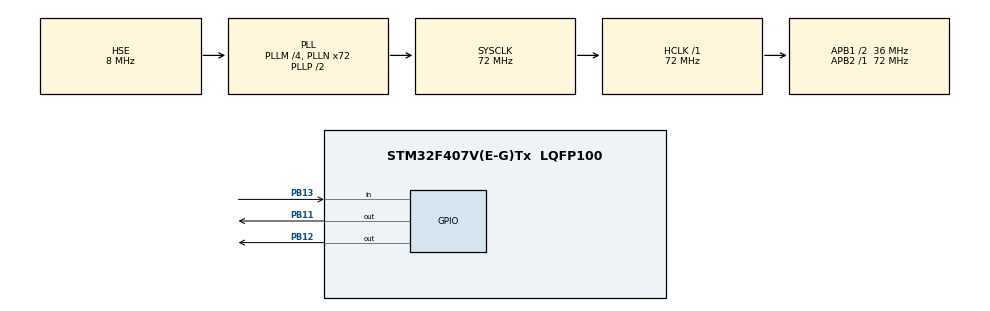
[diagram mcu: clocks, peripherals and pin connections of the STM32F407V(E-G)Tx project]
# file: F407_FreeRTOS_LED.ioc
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FREERTOS.Tasks01=defaultTask,0,128,StartDefaultTask,Default,NULL,Dynamic,NULL,NULL;myTask02,-3,128,StartTask02,Default,NULL,Dynamic,NULL,NULL
FREERTOS.configUSE_NEWLIB_REENTRANT=1
Mcu.Family=STM32F4
Mcu.Name=STM32F407V(E-G)Tx
Mcu.Package=LQFP100
NVIC.PriorityGroup=NVIC_PRIORITYGROUP_4
PB11.Signal=GPIO_Output
PB12.Signal=GPIO_Output
PB13.GPIO_PuPd=GPIO_PULLUP
PB13.Signal=GPIO_Input
PH0-OSC_IN.Mode=HSE-External-Oscillator
PH0-OSC_IN.Signal=RCC_OSC_IN
PH1-OSC_OUT.Mode=HSE-External-Oscillator
PH1-OSC_OUT.Signal=RCC_OSC_OUT
ProjectManager.HeapSize=0x200
ProjectManager.StackSize=0x400
ProjectManager.TargetToolchain=STM32CubeIDE
RCC.48MHZClocksFreq_Value=36000000
RCC.AHBFreq_Value=72000000
RCC.APB1CLKDivider=RCC_HCLK_DIV2
RCC.APB1Freq_Value=36000000
RCC.APB1TimFreq_Value=72000000
RCC.APB2Freq_Value=72000000
RCC.APB2TimFreq_Value=72000000
RCC.CortexFreq_Value=72000000
RCC.HCLKFreq_Value=72000000
RCC.HSE_VALUE=8000000
RCC.HSI_VALUE=16000000
RCC.LSE_VALUE=32768
RCC.PLLM=4
RCC.PLLN=72
RCC.PLLSourceVirtual=RCC_PLLSOURCE_HSE
RCC.SYSCLKFreq_VALUE=72000000
RCC.SYSCLKSource=RCC_SYSCLKSOURCE_PLLCLK
RCC.VCOOutputFreq_Value=144000000
VP_FREERTOS_VS_CMSIS_V1.Mode=CMSIS_V1
board=custom

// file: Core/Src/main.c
/* USER CODE BEGIN Header */
/**
  ******************************************************************************
  * @file           : main.c
  * @brief          : Main program body
  ******************************************************************************
  * @attention
  *
  * Copyright (c) 2024 STMicroelectronics.
  * All rights reserved.
  *
  * This software is licensed under terms that can be found in the LICENSE file
  * in the root directory of this software component.
  * If no LICENSE file comes with this software, it is provided AS-IS.
  *
  ******************************************************************************
  */
/* USER CODE END Header */
#include "main.h"
#include "cmsis_os.h"
#include "gpio.h"

void SystemClock_Config(void);
void MX_FREERTOS_Init(void);

int main(void)
{

  /* MCU Configuration--------------------------------------------------------*/

  /* Reset of all peripherals, Initializes the Flash interface and the Systick. */
  HAL_Init();

  /* Configure the system clock */
  SystemClock_Config();

  /* Initialize all configured peripherals */
  MX_GPIO_Init();

  /* Call init function for freertos objects (in cmsis_os2.c) */
  MX_FREERTOS_Init();

  /* Start scheduler */
  osKernelStart();

  /* We should never get here as control is now taken by the scheduler */

  /* Infinite loop */
  while (1)
  {

  }
}

void SystemClock_Config(void)
{
  RCC_OscInitTypeDef RCC_OscInitStruct = {0};
  RCC_ClkInitTypeDef RCC_ClkInitStruct = {0};

  /** Configure the main internal regulator output voltage
  */
  __HAL_RCC_PWR_CLK_ENABLE();
  __HAL_PWR_VOLTAGESCALING_CONFIG(PWR_REGULATOR_VOLTAGE_SCALE1);

  /** Initializes the RCC Oscillators according to the specified parameters
  * in the RCC_OscInitTypeDef structure.
  */
  RCC_OscInitStruct.OscillatorType = RCC_OSCILLATORTYPE_HSE;
  RCC_OscInitStruct.HSEState = RCC_HSE_ON;
  RCC_OscInitStruct.PLL.PLLState = RCC_PLL_ON;
  RCC_OscInitStruct.PLL.PLLSource = RCC_PLLSOURCE_HSE;
  RCC_OscInitStruct.PLL.PLLM = 4;
  RCC_OscInitStruct.PLL.PLLN = 72;
  RCC_OscInitStruct.PLL.PLLP = RCC_PLLP_DIV2;
  RCC_OscInitStruct.PLL.PLLQ = 4;
  if (HAL_RCC_OscConfig(&RCC_OscInitStruct) != HAL_OK)
  {
    Error_Handler();
  }

  /** Initializes the CPU, AHB and APB buses clocks
  */
  RCC_ClkInitStruct.ClockType = RCC_CLOCKTYPE_HCLK|RCC_CLOCKTYPE_SYSCLK
                              |RCC_CLOCKTYPE_PCLK1|RCC_CLOCKTYPE_PCLK2;
  RCC_ClkInitStruct.SYSCLKSource = RCC_SYSCLKSOURCE_PLLCLK;
  RCC_ClkInitStruct.AHBCLKDivider = RCC_SYSCLK_DIV1;
  RCC_ClkInitStruct.APB1CLKDivider = RCC_HCLK_DIV2;
  RCC_ClkInitStruct.APB2CLKDivider = RCC_HCLK_DIV1;

  if (HAL_RCC_ClockConfig(&RCC_ClkInitStruct, FLASH_LATENCY_2) != HAL_OK)
  {
    Error_Handler();
  }
}

void Error_Handler(void)
{
  __disable_irq();
  while (1)
  {
  }
}

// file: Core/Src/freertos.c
/* USER CODE BEGIN Header */
/**
  ******************************************************************************
  * File Name          : freertos.c
  * Description        : Code for freertos applications
  ******************************************************************************
  * @attention
  *
  * Copyright (c) 2024 STMicroelectronics.
  * All rights reserved.
  *
  * This software is licensed under terms that can be found in the LICENSE file
  * in the root directory of this software component.
  * If no LICENSE file comes with this software, it is provided AS-IS.
  *
  ******************************************************************************
  */
/* USER CODE END Header */

#include "FreeRTOS.h"
#include "task.h"
#include "main.h"
#include "cmsis_os.h"

/* USER CODE BEGIN Variables */
StaticTask_t Task04TCB;
StackType_t Task04Stack[128];
TaskHandle_t Task04_Handler;
/* USER CODE END Variables */
osThreadId defaultTaskHandle;
osThreadId myTask02Handle;

/* USER CODE BEGIN FunctionPrototypes */
void Tesk04(void const * argument);
/* USER CODE END FunctionPrototypes */

void StartDefaultTask(void const * argument);
void StartTask02(void const * argument);

void MX_FREERTOS_Init(void); /* (MISRA C 2004 rule 8.1) */

/* GetIdleTaskMemory prototype (linked to static allocation support) */
void vApplicationGetIdleTaskMemory( StaticTask_t **ppxIdleTaskTCBBuffer, StackType_t **ppxIdleTaskStackBuffer, uint32_t *pulIdleTaskStackSize );

/* USER CODE BEGIN GET_IDLE_TASK_MEMORY */
static StaticTask_t xIdleTaskTCBBuffer;
static StackType_t xIdleStack[configMINIMAL_STACK_SIZE];

void vApplicationGetIdleTaskMemory( StaticTask_t **ppxIdleTaskTCBBuffer, StackType_t **ppxIdleTaskStackBuffer, uint32_t *pulIdleTaskStackSize )
{
  *ppxIdleTaskTCBBuffer = &xIdleTaskTCBBuffer;
  *ppxIdleTaskStackBuffer = &xIdleStack[0];
  *pulIdleTaskStackSize = configMINIMAL_STACK_SIZE;
  /* place for user code */
}
/* USER CODE END GET_IDLE_TASK_MEMORY */

void MX_FREERTOS_Init(void) {

  /* Create the thread(s) */
  /* definition and creation of defaultTask */
  osThreadDef(defaultTask, StartDefaultTask, osPriorityNormal, 0, 128);
  defaultTaskHandle = osThreadCreate(osThread(defaultTask), NULL);

  /* definition and creation of myTask02 */
  osThreadDef(myTask02, StartTask02, osPriorityIdle, 0, 128);
  myTask02Handle = osThreadCreate(osThread(myTask02), NULL);

  /* USER CODE BEGIN RTOS_THREADS */
  Task04_Handler =
		  xTaskCreateStatic(
				  (TaskFunction_t)(Tesk04),
				  "MyTask04",
				  (128),
				  (0),
				  (1),
				  Task04Stack,
				  &Task04TCB
				  );
  /* add threads, ... */
  /* USER CODE END RTOS_THREADS */

}

void StartDefaultTask(void const * argument)
{
  /* USER CODE BEGIN StartDefaultTask */
  /* Infinite loop */
  for(;;)
  {
	  HAL_GPIO_WritePin(GPIOB, GPIO_PIN_11, GPIO_PIN_SET);
	  osDelay(500);
	  HAL_GPIO_WritePin(GPIOB, GPIO_PIN_11, GPIO_PIN_RESET);
	  osDelay(500);
//	  printf("Test");
  }
  /* USER CODE END StartDefaultTask */
}

void StartTask02(void const * argument)
{
  for(;;)
  {
    osDelay(1);
  }
}

/* USER CODE BEGIN Application */
void Tesk04(void const * argument)
{
	for (;;)
	{
		HAL_GPIO_WritePin(GPIOB, GPIO_PIN_12, GPIO_PIN_SET);
		osDelay(500);
		HAL_GPIO_WritePin(GPIOB, GPIO_PIN_12, GPIO_PIN_RESET);
		osDelay(500);
//		vTaskSuspend(defaultTaskHandle);
	}
}
/* USER CODE END Application */
